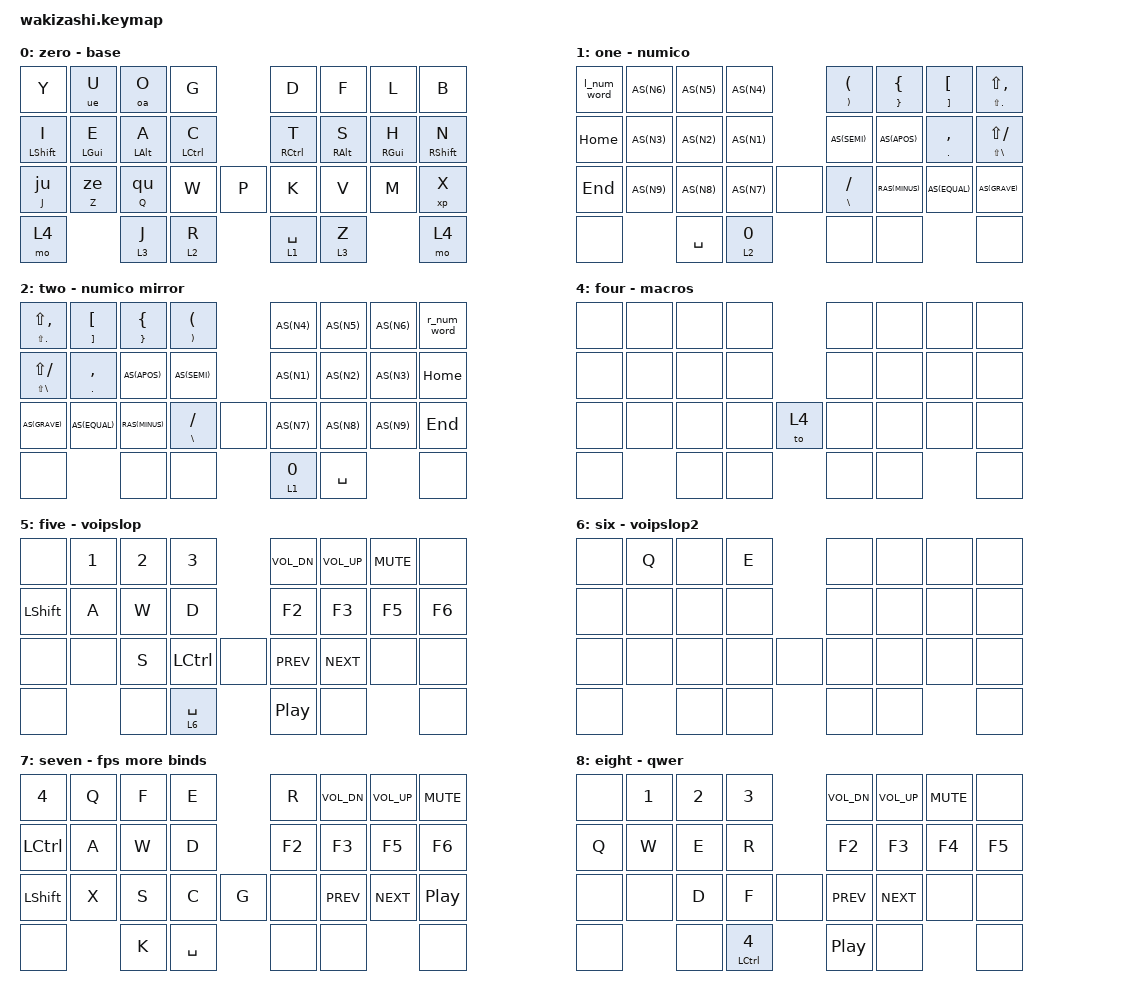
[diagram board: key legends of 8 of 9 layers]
#include "fingermap.h"
#include <behaviors/num_word.dtsi>

/ {
	behaviors {
		hml: home_row_mod_left {
            		hold-trigger-key-positions = <4 5 6 7 12 13 14 15 20 21 22 23 24 28 29 30>; // List of keys on the right
        	};
        	hmr: home_row_mod_right {
            		hold-trigger-key-positions = <0 1 2 3 8 9 10 11 16 17 18 19 20 25 26 27>; // List of keys on the left
        	};		
		l_num_word: left_num_word {
        		#binding-cells = <0>;
		        compatible = "zmk,behavior-num-word";
        		layers = <1>;
        		continue-list = <BSPC DEL DOT COMMA PLUS MINUS STAR FSLH EQUAL>;
        		ignore-numbers;
    		};
		r_num_word: right_num_word {
        		#binding-cells = <0>;
		        compatible = "zmk,behavior-num-word";
        		layers = <2>;
        		continue-list = <BSPC DEL DOT COMMA PLUS MINUS STAR FSLH EQUAL>;
        		ignore-numbers;
    		};
		qumt: qu_mod_tap {
            compatible = "zmk,behavior-hold-tap";
            #binding-cells = <2>;
            flavor = "hold-preferred";
            tapping-term-ms = <150>;
            bindings = <&kp>, <&qu>;
            display-name = "qu Mod-Tap";
        };
		zemt: ze_mod_tap {
            compatible = "zmk,behavior-hold-tap";
            #binding-cells = <2>;
            flavor = "balanced";
            tapping-term-ms = <150>;
            bindings = <&kp>, <&ze>;
            display-name = "ze Mod-Tap";
        };
		jumt: ju_mod_tap {
            compatible = "zmk,behavior-hold-tap";
            #binding-cells = <2>;
            flavor = "balanced";
            tapping-term-ms = <150>;
            bindings = <&kp>, <&ju>;
            display-name = "ju Mod-Tap";
        };
		oamt: oa_mod_tap {
            compatible = "zmk,behavior-hold-tap";
            #binding-cells = <2>;
            flavor = "balanced";
            tapping-term-ms = <150>;
            bindings = <&oa>, <&kp>;
            display-name = "oa Mod-Tap";
        };
		uemt: ue_mod_tap {
            compatible = "zmk,behavior-hold-tap";
            #binding-cells = <2>;
            flavor = "balanced";
            tapping-term-ms = <150>;
            bindings = <&ue>, <&kp>;
            display-name = "ue Mod-Tap";
        };
		xpmt: xp_mod_tap {
            compatible = "zmk,behavior-hold-tap";
            #binding-cells = <2>;
            flavor = "balanced";
            tapping-term-ms = <150>;
            bindings = <&xp>, <&kp>;
            display-name = "xp Mod-Tap";
        };
	};

	keymap {
		compatible = "zmk,keymap";
		zero {
			display-name = "zero - base";
			bindings = <
				&kp Y 			&uemt 0 U 	&oamt 0 O 	&kp G				&kp D 			&kp F 		&kp L 		&kp B
				&hml LSHIFT I 	&hml LGUI E &hml LALT A &hml LCTRL C 		&hmr RCTRL T 	&hmr RALT S &hmr RGUI H &hmr RSHIFT N
				&jumt J 0 		&zemt Z 0 	&qumt Q 0 	&kp W 		&kp P 	&kp K			&kp V 		&kp M 		&xpmt 0 X
				&mo 4 						&lt 3 J 	&lt 2 R 			&lt 1 SPACE 	&lt 3 Z 				&mo 4 	
			>;
		};
		one { 
			display-name = "one - numico";
			bindings = <
				&l_num_word AS(N6) AS(N5) AS(N4) &mt RPAR LPAR &mt RBRC LBRC &mt RBKT LBKT &mt LS(DOT) LS(COMMA)
				&kp HOME AS(N3) AS(N2) AS(N1) AS(SEMI) AS(APOS) &mt DOT COMMA &mt LS(BSLH) LS(FSLH)
				&kp END AS(N9) AS(N8) AS(N7) &none &mt BSLH FSLH RAS(MINUS) AS(EQUAL) AS(GRAVE) 
				&none &kp SPACE &lt 2 N0 &none &none &none 
			>;
		};
		two { 
			display-name = "two - numico mirror";
			bindings = <
				&mt LS(DOT) LS(COMMA) &mt RBKT LBKT &mt RBRC LBRC &mt RPAR LPAR AS(N4) AS(N5) AS(N6) &r_num_word 
				&mt LS(BSLH) LS(FSLH) &mt DOT COMMA AS(APOS) AS(SEMI) AS(N1) AS(N2) AS(N3) &kp HOME  
				AS(GRAVE) AS(EQUAL) RAS(MINUS) &mt BSLH FSLH &none AS(N7) AS(N8) AS(N9) &kp END 
				&none &none &none &lt 1 N0 &kp SPACE &none 
			>;
		};
		three { 
			display-name = "three - navigation and kb functions";
			bindings = <
				&bootloader &none LUM2 &none RUI2 RUM2 RUR2 &none 
				&none &kp HOME &kp PGUP &kp END RHI2 RHM2 RHR2 RHP2
				&none &none &kp PGDN LBI2 &hw_soft_off RBI2 RBM2 &none &none 
				&none &none L2 R2 &none &none 
			>;
		};
		four { 
			display-name = "four - macros";
			bindings = <
				&none &none &none &none &none &none &none &none 
				&none &none &none &none &none &none &none &none
				&none &none &none &none &to 4 &none &none &none &none 
				&none &none &none &none &none &none 
			>;
		};
		five { 
			display-name = "five - voipslop";
			bindings = <
				&none &kp N1 &kp N2 &kp N3 			&kp C_VOL_DN &kp C_VOL_UP &kp C_MUTE &none 
				&kp LSHIFT &kp A &kp W &kp D 		&kp F2 &kp F3 &kp F5 &kp F6 
				&none &none &kp S &kp LCTRL &none 	&kp C_PREV &kp C_NEXT &none &none 
				&none &none &lt 6 SPACE 			&kp C_PP &none &none 
			>;
		};
		six { 
			display-name = "six - voipslop2";
			bindings = <
				&none  &kp Q &none &kp E &none &none &none &none 
				&none &none &none &none &none &none &none &none 
				&none &none &none &none &none &none &none &none &none 
				&none &none &none &none &none &none 
			>;
		};
		seven { 
			display-name = "seven - fps more binds";
			bindings = <
				&kp N4 &kp Q &kp F &kp E &kp R 			&kp C_VOL_DN &kp C_VOL_UP &kp C_MUTE
				&kp LCTRL &kp A &kp W &kp D 			&kp F2 &kp F3 &kp F5 &kp F6 
				&kp LSHIFT &kp X &kp S &kp C &kp G 		&none &kp C_PREV &kp C_NEXT &kp C_PP
				&none &kp K &kp SPACE 				&none &none &none 
			>;
		};
		eight { 
			display-name = "eight - qwer";
			bindings = <
				&none &kp N1 &kp N2 &kp N3 			&kp C_VOL_DN &kp C_VOL_UP &kp C_MUTE &none 
				&kp Q &kp W &kp E &kp R 			&kp F2 &kp F3 &kp F4 &kp F5 
				&none &none &kp D &kp F 	&none 		&kp C_PREV &kp C_NEXT &none &none 
				&none &none &mt LCTRL N4 			&kp C_PP &none &none 
			>;
		};
	};
};

/ {
	combos {
		compatible = "zmk,combos";
		combo_left_numword {
			timeout-ms = <30>;
			key-positions = <1 27>;
			bindings = <&l_num_word>;
			layers = <0>;
		};
		combo_right_numword {
			timeout-ms = <30>;
			key-positions = <6 28>;
			bindings = <&r_num_word>;
			layers = <0>;
		};
		combo_1_game {
			timeout-ms = <70>;
			key-positions = <1 27>;
			bindings = <&kp N1>;
			layers = <7>;
		};
		combo_2_game {
			timeout-ms = <70>;
			key-positions = <2 27>;
			bindings = <&kp N2>;
			layers = <7>;
		};
		combo_3_game {
			timeout-ms = <70>;
			key-positions = <3 27>;
			bindings = <&kp N3>;
			layers = <7>;
		};
		combo_b_game {
			timeout-ms = <50>;
			key-positions = <18 19>;
			bindings = <&kp B>;
			layers = <7 8>;
		};
		combo_y_game {
			timeout-ms = <50>;
			key-positions = <8 27>;
			bindings = <&kp Y>;
			layers = <8>;
		};
		combo_bt_zero {
			timeout-ms = <50>;
			key-positions = <8 9 10 11>;
			bindings = <&bluetooth0>;
			layers = <0>;
		};
		combo_bt_one {
			timeout-ms = <50>;
			key-positions = <12 13 14 15>;
			bindings = <&bluetooth1>;
			layers = <0>;
		};
		combo_usb {
			timeout-ms = <50>;
			key-positions = <18 19 21 22>;
			bindings = <&out OUT_USB>;
			layers = <0>;
		};
		combo_val_layer {
			timeout-ms = <50>;
			key-positions = <9 10 11>;
			bindings = <&to 7>;
			layers = <0>;
		};
		combo_qwer_layer {
			timeout-ms = <50>;
			key-positions = <8 9 11>;
			bindings = <&to 8>;
			layers = <0>;
		};
		combo_voipslop_layer {
			timeout-ms = <50>;
			key-positions = <1 2 3 4 5 6>;
			bindings = <&to 5>;
			layers = <0>;
		};
		combo_defau_layer {
			timeout-ms = <50>;
			key-positions = <10 11 12 13>;
			bindings = <&to 0>;
		};
		combo_enter {
			timeout-ms = <50>;
			key-positions = <11 12>;
			bindings = <&kp ENTER>;
			layers = <0 1 2 3>;
		};
		combo_capsword {
			timeout-ms = <50>;
			key-positions = <8 15>;
			bindings = <&caps_word>;
			layers = <0>;
		};
		combo_up {
			timeout-ms = <50>;
			key-positions = <10 13>;
			bindings = <&kp UP>;
		};
		combo_left {
			timeout-ms = <50>;
			key-positions = <9 12>;
			bindings = <&kp LEFT>;
		};
		combo_down {
			timeout-ms = <50>;
			key-positions = <18 22>;
			bindings = <&kp DOWN>;
		};
		combo_right {
			timeout-ms = <50>;
			key-positions = <11 14>;
			bindings = <&kp RIGHT>;
		};
//formulated
		combo_lhp_lhr { //del
			timeout-ms = <50>;
			key-positions = <8 9>;
			bindings = <LHO>;
			layers = <0 1 2 3>;
		};
		combo_lur_lui { //tab
			timeout-ms = <50>;
			key-positions = <1 3>;
			bindings = <LUO>;
		};
		combo_rui_rur { //esc
			timeout-ms = <50>;
			key-positions = <4 6>;
			bindings = <RUO>;
		};
		combo_rhr_rhp { //back
			timeout-ms = <50>;
			key-positions = <14 15>;
			bindings = <RHO>;
			layers = <0 1 2 3>;
		};
		combo_left_back {
			timeout-ms = <50>;
			key-positions = <8 10>;
			bindings = <&kp BSPC>;
			layers = <0 1 2 3>;
		};
		combo_left_space {
			timeout-ms = <50>;
			key-positions = <3 27>;
			bindings = <&kp SPACE>;
			layers = <0 1 2 3>;
		};
		combo_left_enter {
			timeout-ms = <50>;
			key-positions = <8 11>;
			bindings = <&kp ENTER>;
			layers = <0 1 2 3>;
		};
		combo_left_esc {
			timeout-ms = <50>;
			key-positions = <1 11>;
			bindings = <&kp ESC>;
			layers = <0 1 2 3>;
		};
		combo_right_del {
			timeout-ms = <50>;
			key-positions = <13 15>;
			bindings = <&kp DEL>;
			layers = <0 1 2 3>;
		};
		combo_right_r {
			timeout-ms = <50>;
			key-positions = <4 28>;
			bindings = <&kp R>;
			layers = <0 1 2 3>;
		};
		combo_right_enter {
			timeout-ms = <50>;
			key-positions = <12 15>;
			bindings = <&kp ENTER>;
			layers = <0 1 2 3>;
		};
		combo_right_tab {
			timeout-ms = <50>;
			key-positions = <6 12>;
			bindings = <&kp TAB>;
			layers = <0 1 2 3>;
		};
		combo_j {
			timeout-ms = <50>;
			key-positions = <21 22>;
			bindings = <&kp J>;
			layers = <0>;
		};
		combo_you {
			timeout-ms = <30>;
			key-positions = <0 1>;
			bindings = <&you>;
			layers = <0>;
		};
	};
};



